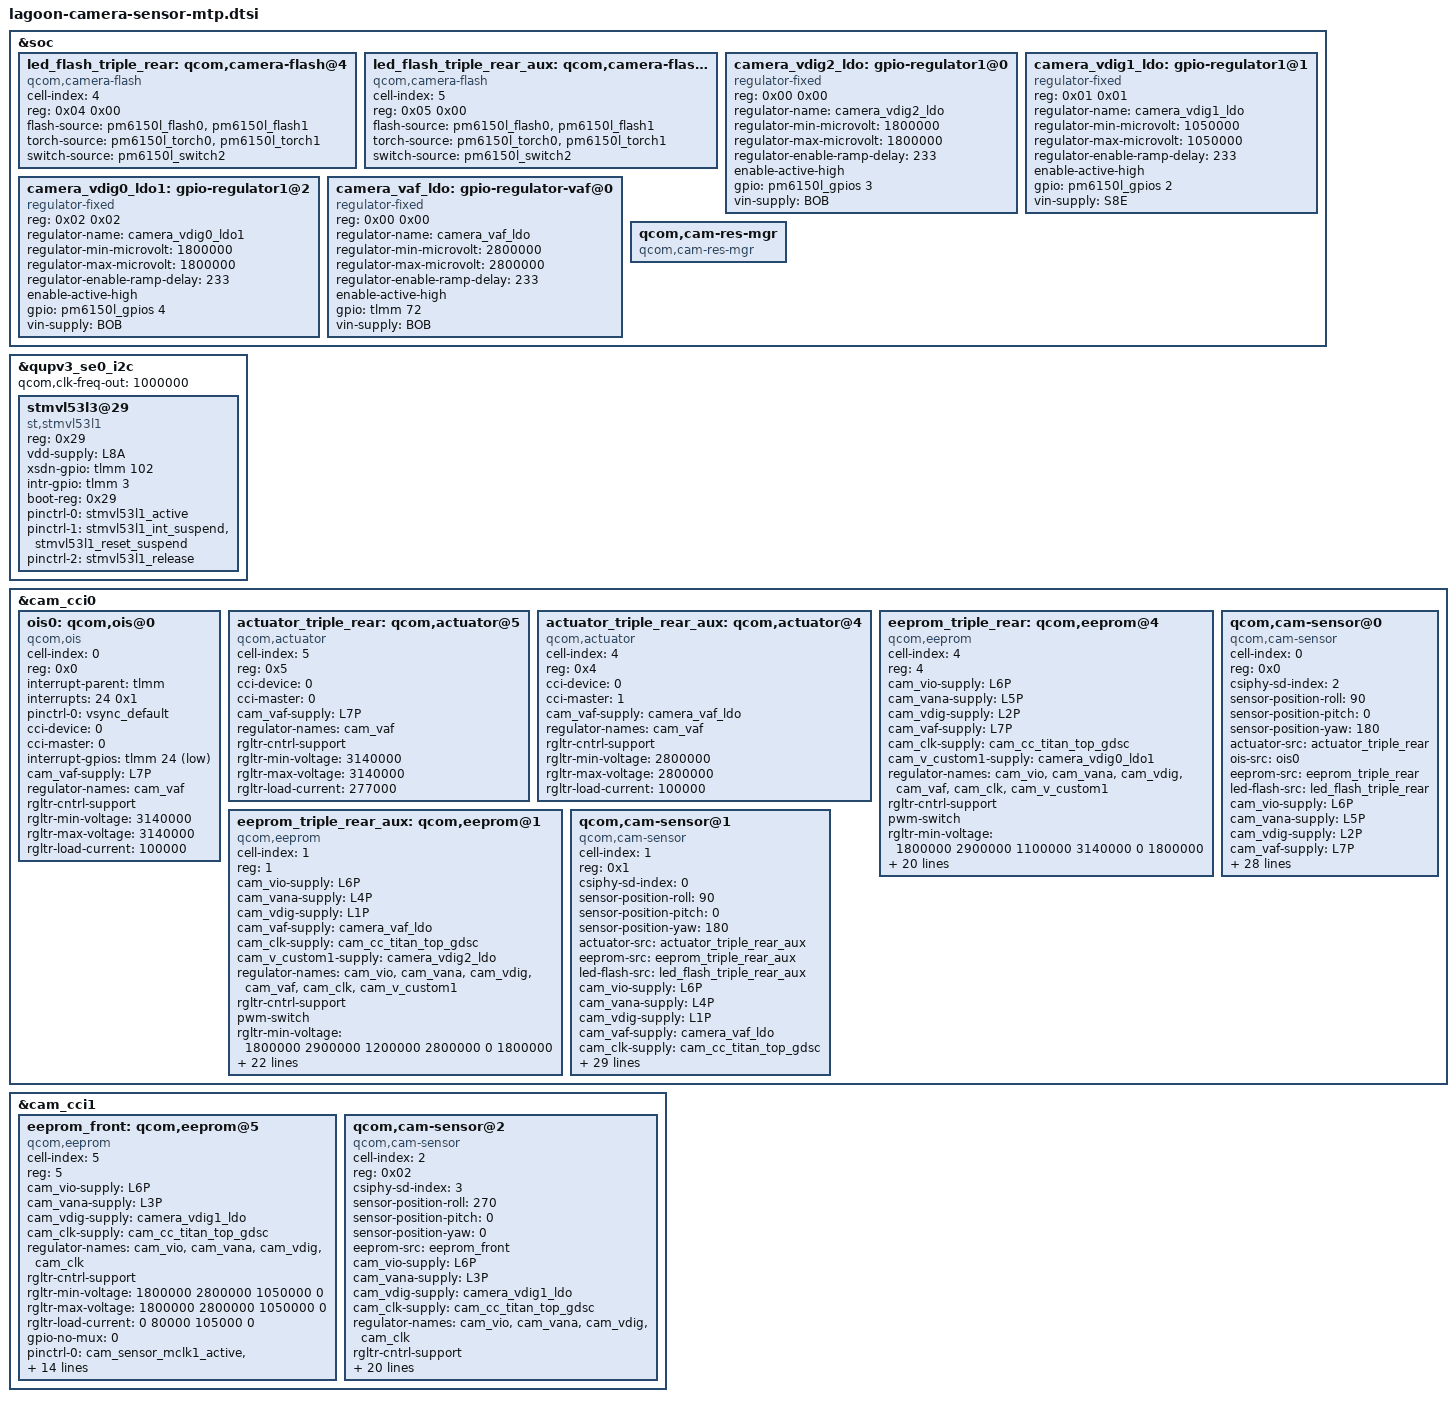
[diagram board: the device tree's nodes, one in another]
#include <dt-bindings/clock/qcom,camcc-lagoon.h>

&soc {
	led_flash_triple_rear: qcom,camera-flash@4 {
		cell-index = <4>;
		reg = <0x04 0x00>;
		compatible = "qcom,camera-flash";
		flash-source = <&pm6150l_flash0 &pm6150l_flash1>;
		torch-source = <&pm6150l_torch0 &pm6150l_torch1>;
		switch-source = <&pm6150l_switch2>;
	};

	led_flash_triple_rear_aux: qcom,camera-flash@5 {
		cell-index = <5>;
		reg = <0x05 0x00>;
		compatible = "qcom,camera-flash";
		flash-source = <&pm6150l_flash0 &pm6150l_flash1>;
		torch-source = <&pm6150l_torch0 &pm6150l_torch1>;
		switch-source = <&pm6150l_switch2>;
	};

	camera_vdig2_ldo: gpio-regulator1@0 {
		compatible = "regulator-fixed";
		reg = <0x00 0x00>;
		regulator-name = "camera_vdig2_ldo";
		regulator-min-microvolt = <1800000>;
		regulator-max-microvolt = <1800000>;
		regulator-enable-ramp-delay = <233>;
		enable-active-high;
		gpio = <&pm6150l_gpios 3 0>;
		vin-supply = <&BOB>;
	};

	camera_vdig1_ldo: gpio-regulator1@1 {
		compatible = "regulator-fixed";
		reg = <0x01 0x01>;
		regulator-name = "camera_vdig1_ldo";
		regulator-min-microvolt = <1050000>;
		regulator-max-microvolt = <1050000>;
		regulator-enable-ramp-delay = <233>;
		enable-active-high;
		gpio = <&pm6150l_gpios 2 0>;
		//pinctrl-names = "default";
		//pinctrl-0 = <&cam_sensor_0_vdig>;
		vin-supply = <&S8E>;
	};

	camera_vdig0_ldo1: gpio-regulator1@2 {
		compatible = "regulator-fixed";
		reg = <0x02 0x02>;
		regulator-name = "camera_vdig0_ldo1";
		regulator-min-microvolt = <1800000>;
		regulator-max-microvolt = <1800000>;
		regulator-enable-ramp-delay = <233>;
		enable-active-high;
		gpio = <&pm6150l_gpios 4 0>;
		vin-supply = <&BOB>;
	};

	camera_vaf_ldo: gpio-regulator-vaf@0 {
		compatible = "regulator-fixed";
		reg = <0x00 0x00>;
		regulator-name = "camera_vaf_ldo";
		regulator-min-microvolt = <2800000>;
		regulator-max-microvolt = <2800000>;
		regulator-enable-ramp-delay = <233>;
		enable-active-high;
		gpio =  <&tlmm 72 0>;
		vin-supply = <&BOB>;
	};

	qcom,cam-res-mgr {
		compatible = "qcom,cam-res-mgr";
		status = "ok";
	};
};

&qupv3_se0_i2c {
	status = "ok";
	qcom,clk-freq-out = <1000000>;
	#address-cells = <1>;
	#size-cells = <0>;

	stmvl53l3@29 {
		compatible = "st,stmvl53l1";
		reg = <0x29>;
		vdd-supply = <&L8A>;
		xsdn-gpio = <&tlmm 102 0>;
		intr-gpio = <&tlmm 3 0>;
		boot-reg = <0x29>;
		status = "ok";
		pinctrl-names = "stmvl53l1_active","stmvl53l1_suspend",
			"stmvl53l1_release";
		pinctrl-0 = <&stmvl53l1_active>;
		pinctrl-1 = <&stmvl53l1_int_suspend &stmvl53l1_reset_suspend>;
		pinctrl-2 = <&stmvl53l1_release>;
	};
};


&cam_cci0 {
	ois0: qcom,ois@0 {
		cell-index = <0>;
		reg = <0x0>;
		compatible = "qcom,ois";
		interrupt-parent = <&tlmm>;
		interrupts = <24 0x1>;
		pinctrl-names = "default";
		pinctrl-0 = <&vsync_default>;
		cci-device = <0>;
		cci-master = <0>;
		interrupt-gpios = <&tlmm 24 0x1>;
		cam_vaf-supply = <&L7P>;
		regulator-names = "cam_vaf";
		rgltr-cntrl-support;
		rgltr-min-voltage = <3140000>;
		rgltr-max-voltage = <3140000>;
		rgltr-load-current = <100000>;
		status = "ok";
	};

	actuator_triple_rear: qcom,actuator@5 {
		cell-index = <5>;
		reg = <0x5>;
		compatible = "qcom,actuator";
		cci-device = <0>;
		cci-master = <0>;
		cam_vaf-supply = <&L7P>;
		regulator-names = "cam_vaf";
		rgltr-cntrl-support;
		rgltr-min-voltage = <3140000>;
		rgltr-max-voltage = <3140000>;
		rgltr-load-current = <277000>;
		status = "ok";
	};

	actuator_triple_rear_aux: qcom,actuator@4 {
		cell-index = <4>;
		reg = <0x4>;
		compatible = "qcom,actuator";
		cci-device = <0>;
		cci-master = <1>;
		cam_vaf-supply = <&camera_vaf_ldo>;
		regulator-names = "cam_vaf";
		rgltr-cntrl-support;
		rgltr-min-voltage = <2800000>;
		rgltr-max-voltage = <2800000>;
		rgltr-load-current = <100000>;
		status = "ok";
	};

	eeprom_triple_rear: qcom,eeprom@4 {
		cell-index = <4>;
		reg = <4>;
		compatible = "qcom,eeprom";
		cam_vio-supply = <&L6P>;
		cam_vana-supply = <&L5P>;
		cam_vdig-supply = <&L2P>;
		cam_vaf-supply = <&L7P>;
		cam_clk-supply = <&cam_cc_titan_top_gdsc>;
		cam_v_custom1-supply = <&camera_vdig0_ldo1>;
		regulator-names = "cam_vio", "cam_vana", "cam_vdig","cam_vaf",
			"cam_clk","cam_v_custom1";
		rgltr-cntrl-support;
		pwm-switch;
		rgltr-min-voltage = <1800000 2900000 1100000 3140000 0 1800000>;
		rgltr-max-voltage = <1800000 2900000 1100000 3140000 0 1800000>;
		rgltr-load-current = <120000 80000 105000 105000 0 120000>;
		gpio-no-mux = <0>;
		pinctrl-names = "cam_default", "cam_suspend";
		pinctrl-0 = <&cam_sensor_mclk0_active
				&cam_sensor_rear0_reset_active>;
		pinctrl-1 = <&cam_sensor_mclk0_suspend
				&cam_sensor_rear0_reset_suspend>;
		gpios = <&tlmm 29 0>,
			<&tlmm 34 0>;
		gpio-reset = <1>;
		gpio-req-tbl-num = <0 1>;
		gpio-req-tbl-flags = <1 0>;
		gpio-req-tbl-label =    "CAMIF_MCLK0",
					"CAM_RESET0";
		sensor-mode = <0>;
		cci-device = <0>;
		cci-master = <0>;
		status = "ok";
		clocks = <&camcc CAM_CC_MCLK0_CLK>;
		clock-names = "cam_clk";
		clock-cntl-level = "turbo";
		clock-rates = <19200000>;
	};

	eeprom_triple_rear_aux: qcom,eeprom@1 {
		cell-index = <1>;
		reg = <1>;
		compatible = "qcom,eeprom";
		cam_vio-supply = <&L6P>;
		cam_vana-supply = <&L4P>;
		cam_vdig-supply = <&L1P>;
		cam_vaf-supply = <&camera_vaf_ldo>;
		cam_clk-supply = <&cam_cc_titan_top_gdsc>;
		cam_v_custom1-supply = <&camera_vdig2_ldo>;
		regulator-names = "cam_vio", "cam_vana", "cam_vdig","cam_vaf",
			"cam_clk","cam_v_custom1";
		rgltr-cntrl-support;
		pwm-switch;
		rgltr-min-voltage = <1800000 2900000 1200000 2800000 0 1800000>;
		rgltr-max-voltage = <1800000 2900000 1200000 2800000 0 1800000>;
		rgltr-load-current = <120000 80000 105000 105000 0 105000>;
		gpio-no-mux = <0>;
		pinctrl-names = "cam_default", "cam_suspend";
		pinctrl-0 = <&cam_sensor_mclk2_active
				&cam_sensor_rear1_reset_active>;
		pinctrl-1 = <&cam_sensor_mclk2_suspend
				&cam_sensor_rear1_reset_suspend>;
		gpios = <&tlmm 31 0>,
			<&tlmm 36 0>,
			<&tlmm 38 0>;
		gpio-reset = <1>;
		gpio-standby = <2>;
		gpio-req-tbl-num = <0 1 2>;
		gpio-req-tbl-flags = <1 0 0>;
		gpio-req-tbl-label =    "CAMIF_MCLK2",
					"CAM_RESET1",
					"CAM_PWDN1";
		sensor-mode = <0>;
		cci-device = <0>;
		cci-master = <1>;
		status = "ok";
		clocks = <&camcc CAM_CC_MCLK2_CLK>;
		clock-names = "cam_clk";
		clock-cntl-level = "turbo";
		clock-rates = <24000000>;
	};

	qcom,cam-sensor@0 { //48M imx582 ois
		cell-index = <0>;
		compatible = "qcom,cam-sensor";
		reg = <0x0>;
		csiphy-sd-index = <2>;
		sensor-position-roll = <90>;
		sensor-position-pitch = <0>;
		sensor-position-yaw = <180>;
		actuator-src = <&actuator_triple_rear>;
		ois-src = <&ois0>;
		eeprom-src = <&eeprom_triple_rear>;
		led-flash-src = <&led_flash_triple_rear>;
		cam_vio-supply = <&L6P>;
		cam_vana-supply = <&L5P>;
		cam_vdig-supply = <&L2P>;
		cam_vaf-supply = <&L7P>;
		cam_clk-supply = <&cam_cc_titan_top_gdsc>;
		cam_v_custom1-supply = <&camera_vdig0_ldo1>;
		regulator-names = "cam_vio", "cam_vana", "cam_vdig","cam_vaf",
			"cam_clk","cam_v_custom1";
		rgltr-cntrl-support;
		pwm-switch;
		rgltr-min-voltage = <1800000 2900000 1100000 3140000 0 1800000>;
		rgltr-max-voltage = <1800000 2900000 1100000 3140000 0 1800000>;
		rgltr-load-current = <120000 80000 105000 105000 0 120000>;
		gpio-no-mux = <0>;
		pinctrl-names = "cam_default", "cam_suspend";
		pinctrl-0 = <&cam_sensor_mclk0_active
				&cam_sensor_rear0_reset_active>;
		pinctrl-1 = <&cam_sensor_mclk0_suspend
				&cam_sensor_rear0_reset_suspend>;
		gpios = <&tlmm 29 0>,
			<&tlmm 34 0>;
		gpio-reset = <1>;
		gpio-req-tbl-num = <0 1>;
		gpio-req-tbl-flags = <1 0>;
		gpio-req-tbl-label =    "CAMIF_MCLK0",
					"CAM_RESET0";
		sensor-mode = <0>;
		cci-device = <0>;
		cci-master = <0>;
		status = "ok";
		clocks = <&camcc CAM_CC_MCLK0_CLK>;
		clock-names = "cam_clk";
		clock-cntl-level = "turbo";
		clock-rates = <19200000>;
	};

	qcom,cam-sensor@1 { //48M imx582 uw
		cell-index = <1>;
		compatible = "qcom,cam-sensor";
		reg = <0x1>;
		csiphy-sd-index = <0>;
		sensor-position-roll = <90>;
		sensor-position-pitch = <0>;
		sensor-position-yaw = <180>;
		actuator-src = <&actuator_triple_rear_aux>;
		eeprom-src = <&eeprom_triple_rear_aux>;
		led-flash-src = <&led_flash_triple_rear_aux>;
		cam_vio-supply = <&L6P>;
		cam_vana-supply = <&L4P>;
		cam_vdig-supply = <&L1P>;
		cam_vaf-supply = <&camera_vaf_ldo>;
		cam_clk-supply = <&cam_cc_titan_top_gdsc>;
		cam_v_custom1-supply = <&camera_vdig2_ldo>;
		regulator-names = "cam_vio", "cam_vana", "cam_vdig","cam_vaf",
			"cam_clk","cam_v_custom1";
		rgltr-cntrl-support;
		pwm-switch;
		rgltr-min-voltage = <1800000 2900000 1200000 2800000 0 1800000>;
		rgltr-max-voltage = <1800000 2900000 1200000 2800000 0 1800000>;
		rgltr-load-current = <120000 80000 105000 105000 0 105000>;
		gpio-no-mux = <0>;
		pinctrl-names = "cam_default", "cam_suspend";
		pinctrl-0 = <&cam_sensor_mclk2_active
				&cam_sensor_rear1_reset_active>;
		pinctrl-1 = <&cam_sensor_mclk2_suspend
				&cam_sensor_rear1_reset_suspend>;
		gpios = <&tlmm 31 0>,
			<&tlmm 36 0>,
			<&tlmm 38 0>;
		gpio-reset = <1>;
		gpio-standby = <2>;
		gpio-req-tbl-num = <0 1 2>;
		gpio-req-tbl-flags = <1 0 0>;
		gpio-req-tbl-label =    "CAMIF_MCLK2",
					"CAM_RESET1",
					"CAM_PWDN1";
		sensor-mode = <0>;
		cci-device = <0>;
		cci-master = <1>;
		status = "ok";
		clocks = <&camcc CAM_CC_MCLK2_CLK>;
		clock-names = "cam_clk";
		clock-cntl-level = "turbo";
		clock-rates = <24000000>;
	};
};

&cam_cci1 {
	eeprom_front: qcom,eeprom@5 {
		cell-index = <5>;
		reg = <5>;
		compatible = "qcom,eeprom";
		cam_vio-supply = <&L6P>;
		cam_vana-supply = <&L3P>;
		cam_vdig-supply = <&camera_vdig1_ldo>;
		cam_clk-supply = <&cam_cc_titan_top_gdsc>;
		regulator-names = "cam_vio", "cam_vana", "cam_vdig",
			"cam_clk";
		rgltr-cntrl-support;
		rgltr-min-voltage = <1800000 2800000 1050000 0>;
		rgltr-max-voltage = <1800000 2800000 1050000 0>;
		rgltr-load-current = <0 80000 105000 0>;
		gpio-no-mux = <0>;
		pinctrl-names = "cam_default", "cam_suspend";
		pinctrl-0 = <&cam_sensor_mclk1_active
				 &cam_sensor_active_front>;
		pinctrl-1 = <&cam_sensor_mclk1_suspend
				 &cam_sensor_suspend_front>;
		gpios = <&tlmm 30 0>,
			<&tlmm 35 0>;
		gpio-reset = <1>;
		gpio-req-tbl-num = <0 1>;
		gpio-req-tbl-flags = <1 0>;
		gpio-req-tbl-label = "CAMIF_MCLK1",
					"CAM_RESET2";
		sensor-mode = <0>;
		cci-device = <1>;
		cci-master = <0>;
		status = "ok";
		clocks = <&camcc CAM_CC_MCLK1_CLK>;
		clock-names = "cam_clk";
		clock-cntl-level = "turbo";
		clock-rates = <24000000>;
	};

	qcom,cam-sensor@2 {	//imx 576
		cell-index = <2>;
		compatible = "qcom,cam-sensor";
		reg = <0x02>;
		csiphy-sd-index = <3>;
		sensor-position-roll = <270>;
		sensor-position-pitch = <0>;
		sensor-position-yaw = <0>;
		eeprom-src = <&eeprom_front>;
		cam_vio-supply = <&L6P>;
		cam_vana-supply = <&L3P>;
		cam_vdig-supply = <&camera_vdig1_ldo>;
		cam_clk-supply = <&cam_cc_titan_top_gdsc>;
		regulator-names = "cam_vio", "cam_vana", "cam_vdig",
			"cam_clk";
		rgltr-cntrl-support;
		pwm-switch;
		rgltr-min-voltage = <1800000 2800000 1050000 0>;
		rgltr-max-voltage = <1800000 2800000 1050000 0>;
		rgltr-load-current = <0 80000 105000 0>;
		gpio-no-mux = <0>;
		pinctrl-names = "cam_default", "cam_suspend";
		pinctrl-0 = <&cam_sensor_mclk1_active
				 &cam_sensor_active_front>;
		pinctrl-1 = <&cam_sensor_mclk1_suspend
				 &cam_sensor_suspend_front>;
		gpios = <&tlmm 30 0>,
			<&tlmm 35 0>;
		gpio-reset = <1>;
		gpio-req-tbl-num = <0 1>;
		gpio-req-tbl-flags = <1 0>;
		gpio-req-tbl-label = "CAMIF_MCLK1",
					"CAM_RESET2";
		sensor-mode = <0>;
		cci-device = <1>;
		cci-master = <0>;
		status = "ok";
		clocks = <&camcc CAM_CC_MCLK1_CLK>;
		clock-names = "cam_clk";
		clock-cntl-level = "turbo";
		clock-rates = <24000000>;
	};
};
